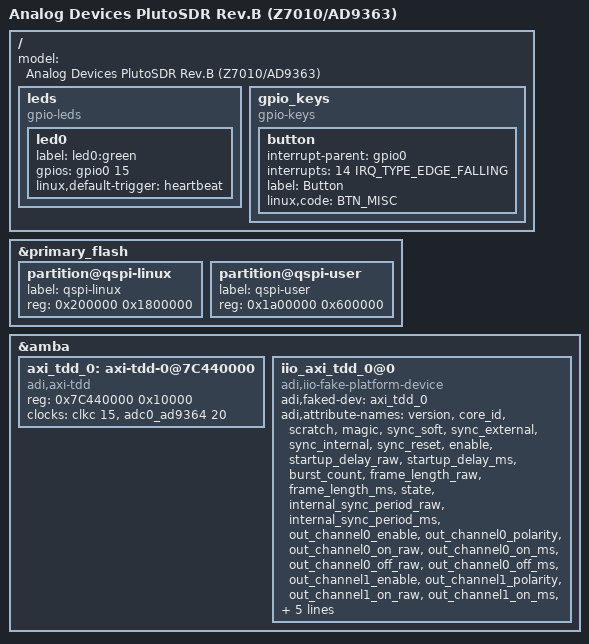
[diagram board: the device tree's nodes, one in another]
// SPDX-License-Identifier: GPL-2.0
/*
 * Analog Devices ADALM Pluto
 * https://wiki.analog.com/university/tools/pluto
 * https://wiki.analog.com/university/tools/pluto/users
 * https://wiki.analog.com/university/tools/pluto/users/firmware
 * https://wiki.analog.com/university/tools/pluto/other
 *
 * hdl_project: <pluto>
 * board_revision: <B>
 *
 * Copyright (C) 2016-2019 Analog Devices Inc.
 */
/dts-v1/;
#include "zynq-pluto-sdr.dtsi"
#include <dt-bindings/input/input.h>
#include <dt-bindings/gpio/gpio.h>
#include <dt-bindings/interrupt-controller/irq.h>

/ {
	model = "Analog Devices PlutoSDR Rev.B (Z7010/AD9363)";

	leds {
		compatible = "gpio-leds";
		led0 {
			label = "led0:green";
			gpios = <&gpio0 15 0>;
			linux,default-trigger = "heartbeat";
		};
	};

	gpio_keys {
		compatible = "gpio-keys";
		#address-cells = <1>;
		#size-cells = <0>;

		button {
			interrupt-parent = <&gpio0>;
			interrupts = <14 IRQ_TYPE_EDGE_FALLING>;
			label = "Button";
			linux,code = <BTN_MISC>;
		};

	};
};

&primary_flash {
	partition@qspi-linux {
		label = "qspi-linux";
		reg = <0x200000 0x1800000>; /* 24M */
	};
	partition@qspi-user {
		label = "qspi-user";
		reg = <0x1a00000 0x600000>; /* 6M */
	};
};

&amba {
	axi_tdd_0: axi-tdd-0@7C440000 {
		compatible = "adi,axi-tdd";
		reg = <0x7C440000 0x10000>;
		clocks = <&clkc 15>, <&adc0_ad9364 20>;
		clock-names = "s_axi_aclk", "intf_clk";
	};

	iio_axi_tdd_0@0 {
		compatible = "adi,iio-fake-platform-device";
		adi,faked-dev = <&axi_tdd_0>;
		adi,attribute-names =
		"version", "core_id", "scratch", "magic",
		"sync_soft", "sync_external", "sync_internal", "sync_reset",
		"enable", "startup_delay_raw", "startup_delay_ms",
		"burst_count", "frame_length_raw", "frame_length_ms",
		"state", "internal_sync_period_raw", "internal_sync_period_ms",
		"out_channel0_enable", "out_channel0_polarity",
		"out_channel0_on_raw", "out_channel0_on_ms",
		"out_channel0_off_raw", "out_channel0_off_ms",
		"out_channel1_enable", "out_channel1_polarity",
		"out_channel1_on_raw", "out_channel1_on_ms",
		"out_channel1_off_raw", "out_channel1_off_ms",
		"out_channel2_enable", "out_channel2_polarity",
		"out_channel2_on_raw", "out_channel2_on_ms",
		"out_channel2_off_raw", "out_channel2_off_ms";
		label = "iio-axi-tdd-0";
	};
};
